# platform_designer_hps_system_hps_0_hps register map
Vendor: default_vendor.com; File version: 0.0
Registers are 32-bit, read-write, reset 0x0 unless marked. A register's access mark holds for its fields unless they carry their own. Offsets are from the block's base; [hi:lo] are bit positions.

## i2c0 — Registers in the I2C module
Base 0xFFC04000
Same registers: i2c1 0xFFC05000, i2c2 0xFFC06000, i2c3 0xFFC07000
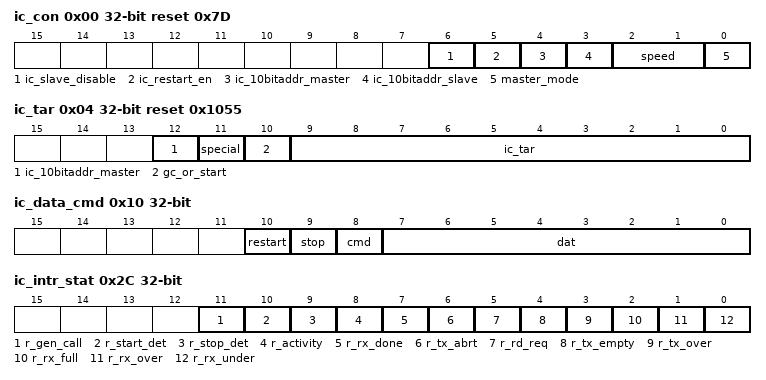
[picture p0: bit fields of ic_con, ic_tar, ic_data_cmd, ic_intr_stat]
0x00 ic_con reset 0x7D — This register can be written only when the I2C is disabled, which corresponds to the Bit [0] of the Enable Register being set to 0. Writes at other times have no effect.
  [6] ic_slave_disable — This bit controls whether I2C has its slave disabled. The slave will be disabled, after reset. NOTE: Software should ensure that if this bit is written with 0, then bit [0] of this register should also be written with a 0.
    1=disable; 0=enable
  [5] ic_restart_en — Determines whether RESTART conditions may be sent when acting as a master. Some older slaves do not support handling RESTART conditions; however, RESTART conditions are used in several I2C operations. When RESTART is disabled, the master is prohibited from performing the following functions - Changing direction within a transfer (split), - Sending a START BYTE, - High-speed mode operation, - Combined format transfers in 7-bit addressing modes, - Read operation with a 10-bit address, - Sending multiple bytes per transfer, By replacing RESTART condition followed by a STOP and a subsequent START condition, split operations are broken down into multiple I2C transfers. If the above operations are performed, it will result in setting bit [6](tx_abort) of the Raw Interrupt Status Register.
    0=disable; 1=enable
  [4] ic_10bitaddr_master — This bit controls whether the I2C starts its transfers in 7-or 10-bit addressing mode when acting as a master.
    0=mstaddr7bit; 1=mstaddr10bit
  [3] ic_10bitaddr_slave — When acting as a slave, this bit controls whether the I2C responds to 7- or 10-bit addresses. In 7-bit addressing, only the lower 7 bits of the Slave Address Register are compared. The I2C responds will only respond to 10-bit addressing transfers that match the full 10 bits of the Slave Address register.
    0=slvaddr7bit; 1=slvaddr10bit
  [2:1] speed — These bits control at which speed the I2C operates, its setting is relevant only if one is operating the I2C in master mode. Hardware protects against illegal values being programmed by software. This field should be programmed only with standard or fast speed.
    1=standard; 2=fast
  [0] master_mode — This bit controls whether the i2c master is enabled. NOTE: Software should ensure that if this bit is written with '1', then bit 6 should also be written with a '1'.
    0=disable; 1=enable
0x04 ic_tar reset 0x1055 — This register can be written to only when the ic_enable register is set to 0. This register is 13 bits wide. All bits can be dynamically updated as long as any set of the following conditions are true, (Enable Register bit 0 is set to 0) or (Enable Register bit 0 is set to 1 AND (I2C is NOT engaged in any Master [tx, rx] operation [ic_status register mst_activity bit 5 is set to 0]) AND (I2C is enabled to operate in Master mode[ic_con bit[0] is set to one]) AND (there are NO entries in the TX FIFO Register [IC_STATUS bit [2] is set to 1])
  [12] ic_10bitaddr_master — This bit controls whether the i2c starts its transfers in 7-bit or 10-bit addressing mode when acting as a master.
    0=start7; 1=start10
  [11] special — This bit indicates whether software performs a General Call or START BYTE command.
    0=gencall; 1=startbyte
  [10] gc_or_start — If bit 11 (SPECIAL) of this Register is set to 1, then this bit indicates whether a General Call or START byte command is to be performed by the I2C or General Call Address after issuing a General Call, only writes may be performed. Attempting to issue a read command results in setting bit 6 (TX_ABRT) of the Raw Interrupt_Status register. The I2C remains in General Call mode until the special bit value (bit 11) is cleared.
    0=gencall; 1=startbyte
  [9:0] ic_tar — This is the target address for any master transaction. When transmitting a General Call, these bits are ignored. To generate a START BYTE, the CPU needs to write only once into these bits. If the ic_tar and ic_sar are the same, loopback exists but the FIFOs are shared between master and slave, so full loopback is not feasible. Only one direction loopback mode is supported (simplex), not duplex. A master cannot transmit to itself; it can transmit to only a slave.
0x08 ic_sar reset 0x55 — Holds Address of Slave
  [9:0] ic_sar — The Slave Address register holds the slave address when the I2C is operating as a slave. For 7-bit addressing, only Field Bits [6:0] of the Slave Address Register are used. This register can be written only when the I2C interface is disabled, which corresponds to field bit 0 of the Enable Register being set to 0. Writes at other times have no effect. Note, the default values cannot be any of the reserved address locations: that is, 0x00 to 0x07, or 0x78 to 0x7f. The correct operation of the device is not guaranteed if you program the Slave Address Register or Target Address Register to a reserved value.
0x10 ic_data_cmd — This is the register the CPU writes to when filling the TX FIFO. Reading from this register returns bytes from RX FIFO.
  [10] restart wo — This bit controls whether a RESTART is issued before the byte is sent or received. 1 = A RESTART is issued before the data is sent/received (according to the value of CMD), regardless of whether or not the transfer direction is changing from the previous command. 0 = A RESTART is issued only if the transfer direction is changing from the previous command.
    1=restart; 0=restart_on_dir_change
  [9] stop wo — This bit controls whether a STOP is issued after the byte is sent or received. 1 = STOP is issued after this byte, regardless of whether or not the Tx FIFO is empty. If the Tx FIFO is not empty, the master immediately tries to start a new transfer by issuing a START and arbitrating for the bus. 0 = STOP is not issued after this byte, regardless of whether or not the Tx FIFO is empty. If the Tx FIFO is not empty, the master continues the current transfer by sending/receiving data bytes according to the value of the CMD bit. If the Tx FIFO is empty, the master holds the SCL line low and stalls the bus until a new command is available in the Tx FIFO.
    1=stop; 0=no_stop
  [8] cmd wo — This bit controls whether a read or a write is performed. This bit does not control the direction when the I2C acts as a slave. It controls only the direction when it acts as a master. When a command is entered in the TX FIFO, this bit distinguishes the write and read commands. In slave-receiver mode, this bit is a 'don't care' because writes to this register are not required. In slave-transmitter mode, a '0' indicates that the CPU data is to be transmitted. When programming this bit, you should remember the following: attempting to perform a read operation after a General Call command has been sent results in a tx_abrt interrupt (bit 6 of the Raw Intr Status Register), unless bit 11 special in the Target Address Register has been cleared. If a '1' is written to this bit after receiving a RD_REQ interrupt, then a tx_abrt interrupt occurs. NOTE: It is possible that while attempting a master I2C read transfer on I2C, a RD_REQ interrupt may have occurred simultaneously due to a remote I2C master addressing I2C. In this type of scenario, I2C ignores the Data Cmd write, generates a tx_abrt interrupt, and waits to service the RD_REQ interrupt.
    1=rd; 0=wr
  [7:0] dat — This Field contains the data to be transmitted or received on the I2C bus. If you are writing to these bits and want to perform a read, bits 7:0 (dat) are ignored by the I2C. However, when you read from this register, these bits return the value of data received on the I2C interface.
0x14 ic_ss_scl_hcnt reset 0x190 — This register sets the SCL clock high-period count for standard speed.
  [15:0] ic_ss_scl_hcnt — This register must be set before any I2C bus transaction can take place to ensure proper I/O timing. This field sets the SCL clock high-period count for standard speed. This register can be written only when the I2C interface is disabled which corresponds to the Enable Register being set to 0. Writes at other times have no effect. The minimum valid value is 6; hardware prevents values less than this being written, and if attempted results in 6 being set. It is readable and writeable. NOTE: This register must not be programmed to a value higher than 65525, because I2C uses a 16-bit counter to flag an I2C bus idle condition when this counter reaches a value of IC_SS_SCL_HCNT + 10.
0x18 ic_ss_scl_lcnt reset 0x1D6 — This register sets the SCL clock low-period count for standard speed
  [15:0] ic_ss_scl_lcnt — This register must be set before any I2C bus transaction can take place to ensure proper I/O timing. This field sets the SCL clock low period count for standard speed. This register can be written only when the I2C interface is disabled which corresponds to the Enable Register register being set to 0. Writes at other times have no effect. The minimum valid value is 8; hardware prevents values less than this from being written, and if attempted, results in 8 being set.
0x1C ic_fs_scl_hcnt reset 0x3C — This register sets the SCL clock high-period count for fast speed
  [15:0] ic_fs_scl_hcnt — This register must be set before any I2C bus transaction can take place to ensure proper I/O timing. This register sets the SCL clock high-period count for fast speed. It is used in high-speed mode to send the Master Code and START BYTE or General CALL. This register goes away and becomes read-only returning 0s if in Standard Speed Mode. This register can be written only when the I2C interface is disabled, which corresponds to the Enable Register being set to 0. Writes at other times have no effect. The minimum valid value is 6; hardware prevents values less than this from being written, and if attempted results in 6 being set.
0x20 ic_fs_scl_lcnt reset 0x82 — This register sets the SCL clock low period count
  [15:0] ic_fs_scl_lcnt — This register must be set before any I2C bus transaction can take place to ensure proper I/O timing. This field sets the SCL clock low period count for fast speed. It is used in high-speed mode to send the Master Code and START BYTE or General CALL. This register can be written only when the I2C interface is disabled, which corresponds to the Enable Register being set to 0. Writes at other times have no effect.The minimum valid value is 8; hardware prevents values less than this being written, and if attempted results in 8 being set.
0x2C ic_intr_stat ro — Each bit in this register has a corresponding mask bit in the Interrupt Mask Register. These bits are cleared by reading the matching Interrupt Clear Register. The unmasked raw versions of these bits are available in the Raw Interrupt Status Register.
  [11] r_gen_call — Set only when a General Call address is received and it is acknowledged. It stays set until it is cleared either by disabling I2C or when the CPU reads bit 0 of the ic_clr_gen_call register. I2C stores the received data in the Rx buffer.
  [10] r_start_det — Indicates whether a START or RESTART condition has occurred on the I2C interface regardless of whether I2C is operating in slave or master mode.
  [9] r_stop_det — Indicates whether a STOP condition has occurred on the I2C interface regardless of whether I2C is operating in slave or master mode.
  [8] r_activity — This bit captures I2C activity and stays set until it is cleared. There are four ways to clear it: - Disabling the I2C - Reading the ic_clr_activity register - Reading the ic_clr_intr register - I2C reset Once this bit is set, it stays set unless one of the four methods is used to clear it. Even if the I2C module is idle, this bit remains set until cleared, indicating that there was activity on the bus.
  [7] r_rx_done — When the I2C is acting as a slave-transmitter, this bit is set to 1, if the master does not acknowledge a transmitted byte. This occurs on the last byte of the transmission, indicating that the transmission is done.
  [6] r_tx_abrt — This bit indicates if I2C, as an I2C transmitter, is unable to complete the intended actions on the contents of the transmit FIFO. This situation can occur both as an I2C master or an I2C slave, and is referred to as a 'transmit abort'.When this bit is set to 1, the ic_tx_abrt_source register indicates the reason why the transmit abort takes places. NOTE: The I2C flushes/resets/empties the TX FIFO whenever this bit is set. The TX FIFO remains in this flushed state until the register ic_clr_tx_abrt is read. Once this read is performed, the TX FIFO is then ready to accept more data bytes from the APB interface.
  [5] r_rd_req — This bit is set to 1 when i2c is acting as a slave and another I2C master is attempting to read data from I2C. The I2C holds the I2C bus in a wait state (SCL=0) until this interrupt is serviced, which means that the slave has been addressed by a remote master that is asking for data to be transferred. The processor must respond to this interrupt and then write the requested data to the IC_DATA_CMD register. This bit is set to 0 just after the processor reads the ic_clr_rd_req register.
  [4] r_tx_empty — This bit is set to 1 when the transmit buffer is at or below the threshold value set in the ic_tx_tl register. It is automatically cleared by hardware when the buffer level goes above the threshold. When the ic_enable bit 0 is 0, the TX FIFO is flushed and held in reset. There the TX FIFO looks like it has no data within it, so this bit is set to 1, provided there is activity in the master or slave state machines. When there is no longer activity, this bit is set to 0.
  [3] r_tx_over — Set during transmit if the transmit buffer is filled to 64 and the processor attempts to issue another I2C command by writing to the Data and Command Register. When the module is disabled, this bit keeps its level until the master or slave state machines goes into idle, then interrupt is cleared.
  [2] r_rx_full — Set when the receive buffer reaches or goes above the Receive FIFO Threshold Value(rx_tl). It is automatically cleared by hardware when buffer level goes below the threshold. If the module is disabled, Bit [0] of the Enable Register set to 0, the RX FIFO is flushed and held in reset; therefore the RX FIFO is not full. So this bit is cleared once the Enable Register Bit 0 is programmed with a 0, regardless of the activity that continues.
  [1] r_rx_over — Set if the receive buffer is completely filled to 64 and an additional byte is received from an external I2C device. The I2C acknowledges this, but any data bytes received after the FIFO is full are lost. If the module is disabled, Enable Register bit[0] is set to 0 this bit keeps its level until the master or slave state machines go into idle, then this interrupt is cleared.
  [0] r_rx_under — Set if the processor attempts to read the receive buffer when it is empty by reading from the Tx Rx Data and Command Register. If the module is disabled, Enable Register is set to 0, this bit keeps its level until the master or slave state machines go into idle, then this interrupt is cleared.
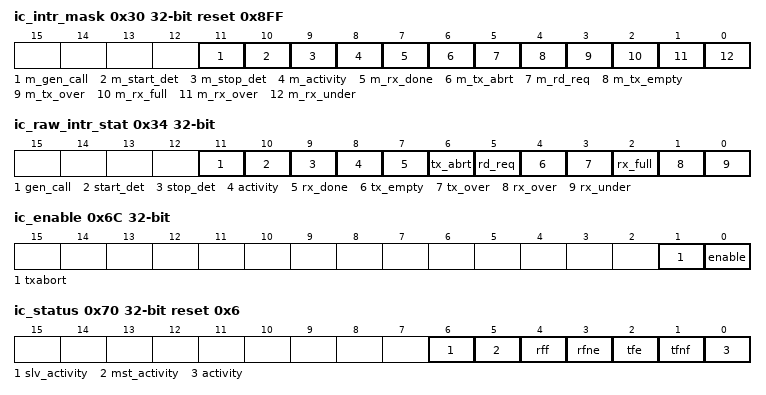
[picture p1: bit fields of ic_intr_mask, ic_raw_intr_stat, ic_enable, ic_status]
0x30 ic_intr_mask reset 0x8FF — These bits mask their corresponding interrupt status bits.
  [11] m_gen_call — Set only when a General Call address is received and it is acknowledged. It stays set until it is cleared either by disabling I2C or when the CPU reads bit 0 of the ic_clr_gen_call register. I2C stores the received data in the Rx buffer.
  [10] m_start_det — Indicates whether a START or RESTART condition has occurred on the I2C interface regardless of whether I2C is operating in slave or master mode.
  [9] m_stop_det — Indicates whether a STOP condition has occurred on the I2C interface regardless of whether i2c is operating in slave or master mode.
  [8] m_activity — This bit captures i2c activity and stays set until it is cleared. There are four ways to clear it: - Disabling the i2c - Reading the ic_clr_activity register - Reading the ic_clr_intr register - System reset Once this bit is set, it stays set unless one of the four methods is used to clear it. Even if the I2C module is idle, this bit remains set until cleared, indicating that there was activity on the bus.
  [7] m_rx_done — When the I2C is acting as a slave-transmitter, this bit is set to 1, if the master does not acknowledge a transmitted byte. This occurs on the last byte of the transmission, indicating that the transmission is done.
  [6] m_tx_abrt — This bit indicates if I2C, as an I2C transmitter, is unable to complete the intended actions on the contents of the transmit FIFO. This situation can occur both as an I2C master or an I2C slave, and is referred to as a 'transmit abort'. When this bit is set to 1, the ic_tx_abrt_source register indicates the reason why the transmit abort takes places. NOTE: The I2C flushes/resets/empties the TX FIFO whenever this bit is set. The TX FIFO remains in this flushed state until the register ic_clr_tx_abrt is read. Once this read is performed, the TX FIFO is then ready to accept more data bytes from the APB interface.
  [5] m_rd_req — This bit is set to 1 when I2C is acting as a slave and another I2C master is attempting to read data from I2C. The I2C holds the I2C bus in a wait state (SCL=0) until this interrupt is serviced, which means that the slave has been addressed by a remote master that is asking for data to be transferred. The processor must respond to this interrupt and then write the requested data to the ic_data_cmd register. This bit is set to 0 just after the processor reads the ic_clr_rd_req register.
  [4] m_tx_empty — This bit is set to 1 when the transmit buffer is at or below the threshold value set in the ic_tx_tl register. It is automatically cleared by hardware when the buffer level goes above the threshold. When the ic_enable bit 0 is 0, the TX FIFO is flushed and held in reset. There the TX FIFO looks like it has no data within it, so this bit is set to 1, provided there is activity in the master or slave state machines. When there is no longer activity, then this bit is set to 0.
  [3] m_tx_over — Set during transmit if the transmit buffer is filled to 64 and the processor attempts to issue another I2C command by writing to the ic_data_cmd register. When the module is disabled, this bit keeps its level until the master or slave state machines go into idle, then this interrupt is cleared.
  [2] m_rx_full — Set when the receive buffer reaches or goes above the RX_TL threshold in the ic_rx_tl register. It is automatically cleared by hardware when buffer level goes below the threshold. If the module is disabled ic_enable[0]=0, the RX FIFO is flushed and held in reset; therefore the RX FIFO is not full. So this bit is cleared once the ic_enable bit 0 is programmed with a 0, regardless of the activity that continues.
  [1] m_rx_over — Set if the receive buffer is completely filled to 64 and an additional byte is received from an external I2C device. The I2C acknowledges this, but any data bytes received after the FIFO is full are lost. If the module is disabled ic_enable[0]=0, this bit keeps its level until the master or slave state machines go into idle, then this interrupt is cleared.
  [0] m_rx_under — Set if the processor attempts to read the receive buffer when it is empty by reading from the ic_data_cmd register. If the module is disabled ic_enable[0]=0, this bit keeps its level until the master or slave state machines go into idle, and then this interrupt is cleared.
0x34 ic_raw_intr_stat ro — Unlike the ic_intr_stat register, these bits are not masked so they always show the true status of the I2C.
  [11] gen_call — Set only when a General Call address is received and it is acknowledged. It stays set until it is cleared either by disabling I2C or when the CPU reads bit 0 of the ic_clr_gen_call register. I2C stores the received data in the Rx buffer.
  [10] start_det — Indicates whether a START or RESTART condition has occurred on the I2C interface regardless of whether I2C is operating in slave or master mode.
  [9] stop_det — Indicates whether a STOP condition has occurred on the I2C interface regardless of whether I2C is operating in slave or master mode.
  [8] activity — This bit captures i2c activity and stays set until it is cleared. There are four ways to clear it: - Disabling the I2C - Reading the ic_clr_activity register - Reading the ic_clr_intr register - System reset Once this bit is set, it stays set unless one of the four methods is used to clear it. Even if the i2c module is idle, this bit remains set until cleared, indicating that there was activity on the bus.
  [7] rx_done — When the I2C is acting as a slave-transmitter, this bit is set to 1 if the master does not acknowledge a transmitted byte. This occurs on the last byte of the transmission, indicating that the transmission is done.
  [6] tx_abrt — This bit indicates if I2C, as an I2C transmitter, is unable to complete the intended actions on the contents of the transmit FIFO. This situation can occur both as an I2C master or an I2C slave, and is referred to as a 'transmit abort'. When this bit is set to 1, the IC_TX_ABRT_SOURCE register indicates the reason why the transmit abort takes places. NOTE: The I2C flushes/resets/empties the TX FIFO whenever this bit is set. The TX FIFO remains in this flushed state until the register ic_clr_tx_abrt is read. Once this read is performed, the TX FIFO is then ready to accept more data bytes from the APB interface.
  [5] rd_req — This bit is set to 1 when I2C is acting as a slave and another I2C master is attempting to read data from I2C. The i2c holds the I2C bus in a wait state (SCL=0) until this interrupt is serviced, which means that the slave has been addressed by a remote master that is asking for data to be transferred. The processor must respond to this interrupt and then write the requested data to the ic_data_cmd register. This bit is set to 0 just after the processor reads the ic_clr_rd_req register.
  [4] tx_empty — This bit is set to 1 when the transmit buffer is at or below the threshold value set in the ic_tx_tl register. It is automatically cleared by hardware when the buffer level goes above the threshold. When the IC_ENABLE bit 0 is 0, the TX FIFO is flushed and held in reset. There the TX FIFO looks like it has no data within it, so this bit is set to 1, provided there is activity in the master or slave state machines. When there is no longer activity, then this bit is set to 0.
  [3] tx_over — Set during transmit if the transmit buffer is filled to 64 and the processor attempts to issue another I2C command by writing to the ic_data_cmd register. When the module is disabled, this bit keeps its level until the master or slave state machines go into idle, then this interrupt is cleared.
  [2] rx_full — Set when the receive buffer reaches or goes above the RX_TL threshold in the ic_rx_tl register. It is automatically cleared by hardware when buffer level goes below the threshold. If the module is disabled ic_enable[0]=0, the RX FIFO is flushed and held in reset; therefore the RX FIFO is not full. So this bit is cleared once the ic_enable bit 0 is programmed with a 0, regardless of the activity that continues.
  [1] rx_over — Set if the receive buffer is completely filled to 64 and an additional byte is received from an external I2C device. The I2C acknowledges this, but any data bytes received after the FIFO is full are lost. If the module is disabled ic_enable[0]=0), this bit keeps its level until the master or slave state machines go into then, this interrupt is cleared.
  [0] rx_under — Set if the processor attempts to read the receive buffer when it is empty by reading from the ic_data_cmd register. If the module is disabled ic_enable[0]=0, this bit keeps its level until the master or slave state machines go into idle, then this interrupt is cleared.
0x38 ic_rx_tl — I2C Receive FIFO Threshold Register.
  [7:0] rx_tl — Controls the level of entries (or above) that triggers the RX_FULL interrupt (bit 2 in IC_RAW_INTR_STAT register). The valid range is 0-255, with the additional restriction that hardware does not allow this value to be set to a value larger than the depth of the buffer. If an attempt is made to do that, the actual value set will be the maximum depth of the buffer. A value of 0 sets the threshold for 1 entry, and a value of 255 sets the threshold for 256 entries.
0x3C ic_tx_tl — Sets FIFO depth for Interrupt.
  [7:0] tx_tl — Controls the level of entries (or below) that trigger the TX_EMPTY interrupt (bit 4 in ic_raw_intr_stat register). The valid range is 0-255, with the additional restriction that it may not be set to value larger than the depth of the buffer. If an attempt is made to do that, the actual value set will be the maximum depth of the buffer. A value of 0 sets the threshold for 0 entries, and a value of 255 sets the threshold for 255 entries.
0x40 ic_clr_intr ro — Controls Interrupts
  [0] clr_intr — Read this register to clear the combined interrupt, all individual interrupts, and the IC_TX_ABRT_SOURCE register. This bit does not clear hardware clearable interrupts but software clearable interrupts. Refer to Bit 9 of the ic_tx_abrt_source register for an exception to clearing ic_tx_abrt_source.
0x44 ic_clr_rx_under ro — Rx Under Interrupt Bits.
  [0] clr_rx_under — Read this register to clear the RX_UNDER interrupt bit 0 of the ic_raw_intr_stat register.
0x48 ic_clr_rx_over ro — Clears Rx over Interrupt Bit
  [0] clr_rx_over — Read this register to clear the RX_OVER interrupt bit 1 of the ic_raw_intr_stat register.
0x4C ic_clr_tx_over ro — Clears Over Interrupts
  [0] clr_tx_over — Read this register to clear the TX_OVER interrupt (bit 3) of the ic_raw_intr_stat register.
0x50 ic_clr_rd_req ro — Clear RD_REQ Interrupt Register
  [0] clr_rd_req — Read this register to clear the RD_REQ interrupt (bit 5) of the ic_raw_intr_stat register.
0x54 ic_clr_tx_abrt ro — Clear TX_ABRT Interrupt
  [0] clr_tx_abort — Read this register to clear the TX_ABRT interrupt (bit 6) of the ic_raw_intr_stat register, and the ic_tx_abrt_source register. This also releases the TX FIFO from the flushed/reset state, allowing more writes to the TX FIFO. Refer to Bit 9 of the ic_tx_abrt_source register for an exception to clearing ic_tx_abrt_source.
0x58 ic_clr_rx_done ro — Clear RX_DONE Interrupt Register
  [0] clr_rx_done — Read this register to clear the RX_DONE interrupt (bit 7) of the ic_raw_intr_stat register.
0x5C ic_clr_activity ro — Clears ACTIVITY Interrupt
  [0] clr_activity — Reading this register clears the ACTIVITY interrupt if the I2C is not active anymore. If the I2C module is still active on the bus, the ACTIVITY interrupt bit continues to be set. It is automatically cleared by hardware if the module is disabled and if there is no further activity on the bus. The value read from this register to get status of the ACTIVITY interrupt (bit 8) of the ic_raw_intr_stat register.
0x60 ic_clr_stop_det ro — Clear Interrupts.
  [0] clr_stop_det — Read this register to clear the clr_stop_det interrupt (bit 9) of the ic_raw_intr_stat register.
0x64 ic_clr_start_det ro — Clears START_DET Interrupt
  [0] clr_start_det — Read this register to clear the start_det interrupt (bit 10) of the ic_raw_intr_stat register.
0x68 ic_clr_gen_call ro — Clear GEN_CALL Interrupt Register
  [0] clr_gen_call — Read this register to clear the GEN_CALL interrupt (bit 11) of ic_raw_intr_stat register.
0x6C ic_enable — Enable and disable i2c operation
  [1] txabort — Write 1 does a TX abort. Self cleared on abort completion
  [0] enable — Controls whether the I2C is enabled. Software can disable I2C while it is active. However, it is important that care be taken to ensure that I2C is disabled properly. When the I2C is disabled, the following occurs: The TX FIFO and RX FIFO get flushed. Status bits in the IC_INTR_STAT register are still active until I2C goes into IDLE state. If the module is transmitting, it stops as well as deletes the contents of the transmit buffer after the current transfer is complete. If the module is receiving, the I2C stops the current transfer at the end of the current byte and does not acknowledge the transfer. The l4_sp_clk synchronizes pclk and ic_clk. The register ic_enable_status is added to allow software to determine when the hardware has completely shutdown in response to the IC_ENABLE register being set from 1 to 0. Only one register is required to be monitored. Procedure for Disabling I2C 1. Define a timer interval (ti2c_poll) equal to the 10 times the signaling period for the highest I2C transfer speed used in the system and supported by I2C. For example, if the highest I2C transfer mode is 400 kb/s, then this ti2c_poll is 25us. 2. Define a maximum time-out parameter, MAX_T_POLL_COUNT, such that if any repeated polling operation exceeds this maximum value, an error is reported. 3. Execute a blocking thread/process/function that prevents any further I2C master transactions to be started by software, but allows any pending transfers to be completed. 4. The variable POLL_COUNT is initialized to zero. 5. Set IC_ENABLE to 0. 6. Read the IC_ENABLE_STATUS register and test the IC_EN bit (bit 0). Increment POLL_COUNT by one. If POLL_COUNT >= MAX_T_POLL_COUNT, exit with the relevant error code. 7. If IC_ENABLE_STATUS[0] is 1, then sleep for ti2c_poll and proceed to the previous step. Otherwise, exit with a relevant success code.
    0=disable; 1=enable
0x70 ic_status ro reset 0x6 — This is a read-only register used to indicate the current transfer status and FIFO status. The status register may be read at any time. None of the bits in this register request an interrupt.When the I2C is disabled by writing 0 in bit 0 of the ic_enable register: - Bits 1 and 2 are set to 1 - Bits 3 and 4 are set to 0 When the master or slave state machines goes to idle - Bits 5 and 6 are set to 0
  [6] slv_activity — Slave FSM Activity Status. When the Slave Finite State Machine (FSM) is not in the IDLE state, this bit is set.
    0=idle; 1=notidle
  [5] mst_activity — When the Master Finite State Machine (FSM) is not in the IDLE state, this bit is set. Note:IC_STATUS[0]-that is, ACTIVITY bit-is the OR of SLV_ACTIVITY and MST_ACTIVITY bits.
    0=idle; 1=notidle
  [4] rff — Receive FIFO Completely Full.
    0=notfull; 1=full
  [3] rfne — Receive FIFO Not Empty.
    0=empty; 1=notempty
  [2] tfe — Transmit FIFO Empty.
    0=notempty; 1=empty
  [1] tfnf — Transmit Fifo Full
    0=full; 1=notfull
  [0] activity — I2C Activity.
0x74 ic_txflr ro — This register contains the number of valid data entries in the transmit FIFO buffer. It is cleared whenever: - The I2C is disabled - There is a transmit abort that is, TX_ABRT bit is set in the ic_raw_intr_stat register. The slave bulk transmit mode is aborted The register increments whenever data is placed into the transmit FIFO and decrements when data is taken from the transmit FIFO.
  [6:0] txflr — Transmit FIFO Level.Contains the number of valid data entries in the transmit FIFO.
0x78 ic_rxflr ro — This register contains the number of valid data entries in the receive FIFO buffer. It is cleared whenever: - The I2C is disabled - Whenever there is a transmit abort caused by any of the events tracked in ic_tx_abrt_source The register increments whenever data is placed into the receive FIFO and decrements when data is taken from the receive FIFO.
  [6:0] rxflr — Receive FIFO Level. Contains the number of valid data entries in the receive FIFO.
0x7C ic_sda_hold reset 0x1 — This register controls the amount of time delay (in terms of number of l4_sp_clk clock periods) introduced in the falling edge of SCL, relative to SDA changing, when I2C services a read request in a slave-transmitter operation. The relevant I2C requirement is thd:DAT as detailed in the I2C Bus Specification.
  [15:0] ic_sda_hold — Program to a minimum 0f 300ns.
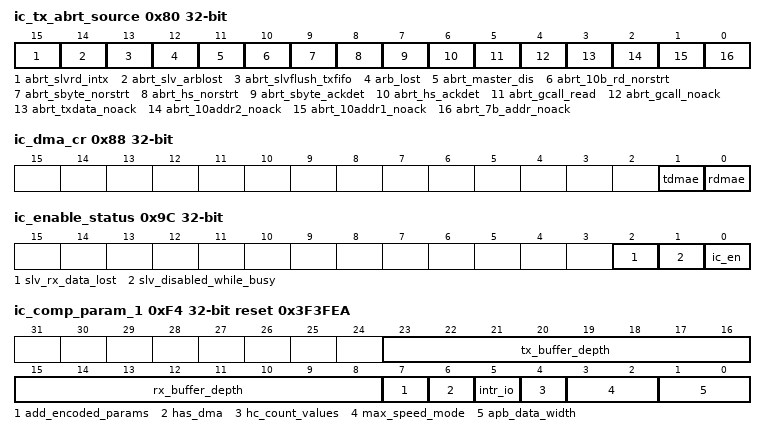
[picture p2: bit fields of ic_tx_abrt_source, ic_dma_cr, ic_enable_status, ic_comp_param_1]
0x80 ic_tx_abrt_source — This register has 16 bits that indicate the source of the TX_ABRT bit. Except for Bit 9, this register is cleared whenever the ic_clr_tx_abrt register or the ic_clr_intr register is read. To clear Bit 9, the source of the abrt_sbyte_norstrt must be fixed first; RESTART must be enabled (ic_con[5]=1), the special bit must be cleared (ic_tar[11]), or the gc_or_start bit must be cleared (ic_tar[10]). Once the source of the abrt_sbyte_norstrt is fixed, then this bit can be cleared in the same manner as other bits in this register. If the source of the abrt_sbyte_norstrt is not fixed before attempting to clear this bit, Bit 9 clears for one cycle and is then re-asserted.
  [15] abrt_slvrd_intx — When the processor side responds to a slave mode request for data to be transmitted to a remote master and user writes a 1 in CMD (bit 8) of IC_DATA_CMD register. Role of I2C: Slave-Transmitter
  [14] abrt_slv_arblost — Slave lost the bus while transmitting data to a remote master. IC_TX_ABRT_SOURCE[12] is set at the same time. Note: Even though the slave never 'owns' the bus, something could go wrong on the bus. This is a fail safe check. For instance, during a data transmission at the low-to-high transition of SCL, if what is on the data bus is not what is supposed to be transmitted, then i2c no longer own the bus. Role of I2C: Slave-Transmitter
  [13] abrt_slvflush_txfifo — Slave has received a read command and some data exists in the TX FIFO so the slave issues a TX_ABRT interrupt to flush old data in TX FIFO. Role of I2C: Slave-Transmitter
  [12] arb_lost — Master has lost arbitration, or if IC_TX_ABRT_SOURCE[14] is also set, then the slave transmitter has lost arbitration. Note: I2C can be both master and slave at the same time. Role of i2c: Master-Transmitter or Slave-Transmitter
  [11] abrt_master_dis — User tries to initiate a Master operation with the Master mode disabled. Role of I2C: Master-Transmitter or Master-Receiver
  [10] abrt_10b_rd_norstrt — The restart is disabled (ic_restart_en bit (ic_con[5]) =0) and the master sends a read command in 10-bit addressing mode. Role of I2C: Master-Receiver
  [9] abrt_sbyte_norstrt — To clear Bit 9, the source of then abrt_sbyte_norstrt must be fixed first; restart must be enabled (ic_con[5]=1), the SPECIAL bit must be cleared (ic_tar[11]), or the GC_OR_START bit must be cleared (ic_tar[10]). Once the source of the abrt_sbyte_norstrt is fixed, then this bit can be cleared in the same manner as other bits in this register. If the source of the abrt_sbyte_norstrt is not fixed before attempting to clear this bit, bit 9 clears for one cycle and then gets reasserted. 1: The restart is disabled (IC_RESTART_EN bit (ic_con[5]) =0) and the user is trying to send a START Byte. Role of I2C: Master
  [8] abrt_hs_norstrt — The restart is disabled (IC_RESTART_EN bit (IC_CON[5]) =0) and the user is trying to use the master to transfer data in High Speed mode. Role of i2c: Master-Transmitter or Master-Receiver
  [7] abrt_sbyte_ackdet — Master has sent a START Byte and the START Byte was acknowledged (wrong behavior). Role of i2c: Master
  [6] abrt_hs_ackdet — Master is in High Speed mode and the High Speed Master code was acknowledged (wrong behavior). Role of i2c: Master
  [5] abrt_gcall_read — i2c in master mode sent a General Call but the user programmed the byte following the General Call to be a read from the bus (IC_DATA_CMD[9] is set to 1). Role of i2c: Master-Transmitter
  [4] abrt_gcall_noack — i2c in master mode sent a General Call and no slave on the bus acknowledged the General Call. Role of i2c: Master-Transmitter
  [3] abrt_txdata_noack — This is a master-mode only bit. Master has received an acknowledgement for the address, but when it sent data byte(s) following the address, it did not receive an acknowledge from the remote slave(s). Role of i2c: Master-Transmitter
  [2] abrt_10addr2_noack — Master is in 10-bit address mode and the second address byte of the 10-bit address was not acknowledged by any slave. Role of i2c: Master-Transmitter or Master-Receiver
  [1] abrt_10addr1_noack — Master is in 10-bit address mode and the first 10-bit address byte was not acknowledged by any slave. Role of i2c: Master-Transmitter or Master-Receiver
  [0] abrt_7b_addr_noack — Master is in 7-bit addressing mode and the address sent was not acknowledged by any slave. Role of i2c: Master-Transmitter or Master-Receiver
0x84 ic_slv_data_nack_only — The register is used to generate a NACK for the data part of a transfer when i2c is acting as a slave-receiver.
  [0] nack — This Bit control Nack generation
    1=afterdbyte; 0=norm
0x88 ic_dma_cr — The register is used to enable the DMA Controller interface operation. There is a separate bit for transmit and receive. This can be programmed regardless of the state of IC_ENABLE.
  [1] tdmae — This bit enables/disables the transmit FIFO DMA channel.
    0=disable; 1=enable
  [0] rdmae — This bit enables/disables the receive FIFO DMA channel.
    0=disable; 1=enable
0x8C ic_dma_tdlr — This register supports DMA Transmit Operation.
  [5:0] dmatdl — This bit field controls the level at which a DMA request is made by the transmit logic. It is equal to the watermark level; that is, the i2c_dma_tx_req signal is generated when the number of valid data entries in the transmit FIFO is equal to or below this field value, and TDMAE = 1.
0x90 ic_dma_rdlr — DMA Control Signals Interface.
  [5:0] dmardl — This bit field controls the level at which a DMA request is made by the receive logic. The watermark level \= DMARDL+1; that is, dma_rx_req is generated when the number of valid data entries in the receive FIFO is equal to or more than this field value + 1, and RDMAE =1. For instance, when DMARDL is 0, then dma_rx_req is asserted when or more data entries are present in the receive FIFO.
0x94 ic_sda_setup reset 0x64 — This register controls the amount of time delay (in terms of number of l4_sp_clk clock periods) introduced in the rising edge of SCL relative to SDA changing by holding SCL low when I2C services a read request while operating as a slave-transmitter. The relevant I2C requirement is tSU:DAT (note 4) as detailed in the I2C Bus Specification. This register must be programmed with a value equal to or greater than 2. Note: The length of setup time is calculated using [(IC_SDA_SETUP - 1) * (l4_sp_clk)], so if the user requires 10 l4_sp_clk periods of setup time, they should program a value of 11. The IC_SDA_SETUP register is only used by the I2C when operating as a slave transmitter.
  [7:0] sda_setup — It is recommended that if the required delay is 1000ns, then for an l4_sp_clk frequency of 10 MHz, ic_sda_setup should be programmed to a value of 11.
0x98 ic_ack_general_call reset 0x1 — The register controls whether i2c responds with a ACK or NACK when it receives an I2C General Call address.
  [0] ack_gen_call — When an ACK is asserted, (by asserting i2c_out_data) when it receives a General call. Otherwise, i2c responds with a NACK (by negating i2c_out_data).
    0=nack; 1=ack
0x9C ic_enable_status ro — This register is used to report the i2c hardware status when the IC_ENABLE register is set from 1 to 0; that is, when i2c is disabled. If IC_ENABLE has been set to 1, bits 2:1 are forced to 0, and bit 0 is forced to 1. If IC_ENABLE has been set to 0, bits 2:1 are only valid as soon as bit 0 is read as '0'. Note: When ic_enable has been written with '0' a delay occurs for bit 0 to be read as '0' because disabling the i2c depends on I2C bus activities.
  [2] slv_rx_data_lost — This bit indicates if a Slave-Receiver operation has been aborted with at least one data byte received from an I2C transfer due to the setting of IC ENABLE from 1 to 0. When read as 1, i2c is deemed to have been actively engaged in an aborted I2C transfer (with matching address) and the data phase of the I2C transfer has been entered, even though a data byte has been responded with a NACK. NOTE: If the remote I2C master terminates the transfer with a STOP condition before the i2c has a chance to NACK a transfer, and ic_enable has been set to 0, then this bit is also set to 1. When read as 0, i2c is deemed to have been disabled without being actively involved in the data phase of a Slave-Receiver transfer. NOTE: The CPU can safely read this bit when IC_EN (bit 0) is read as 0.
  [1] slv_disabled_while_busy — This bit indicates if a potential or active Slave operation has been aborted due to the setting of the ic_enable register from 1 to 0. This bit is set when the CPU writes a 0 to the ic_enable register while: (a) I2C is receiving the address byte of the Slave-Transmitter operation from a remote master; OR, (b) address and data bytes of the Slave-Receiver operation from a remote master. When read as 1, I2C is deemed to have forced a NACK during any part of an I2C transfer, irrespective of whether the I2C address matches the slave address set in i2c (IC_SAR register) OR if the transfer is completed before IC_ENABLE is set to 0 but has not taken effect. NOTE: If the remote I2C master terminates the transfer with a STOP condition before the i2c has a chance to NACK a transfer, and IC_ENABLE has been set to 0, then this bit will also be set to 1. When read as 0, i2c is deemed to have been disabled when there is master activity, or when the I2C bus is idle. NOTE: The CPU can safely read this bit when IC_EN (bit 0) is read as 0.
  [0] ic_en — This bit always reflects the value driven on the output port ic_en. Not used in current application. When read as 1, i2c is deemed to be in an enabled state. When read as 0, i2c is deemed completely inactive. NOTE: The CPU can safely read this bit anytime. When this bit is read as 0, the CPU can safely read slv_rx_data_lost (bit 2) and slv_disabled_while_busy (bit 1).
0xA0 ic_fs_spklen reset 0x2 — This register is used to store the duration, measured in ic_clk cycles, of the longest spike that is filtered out by the spike suppression logic when the component is operating in SS or FS modes.
  [7:0] spklen — This register must be set before any I2C bus transaction can take place to ensure stable operation. This register sets the duration, measured in ic_clk cycles, of the longest spike in the SCL or SDA lines that are filtered out by the spike suppression logic. This register can be written only when the I2C interface is disabled, which corresponds to the IC_ENABLE register being set to 0. Writes at other times have no effect. The minimum valid value is 1; hardware prevents values less than this being written, and if attempted results in 2 being set.
0xF4 ic_comp_param_1 ro reset 0x3F3FEA — This is a constant read-only register that contains encoded information about the component's parameter settings.
  [23:16] tx_buffer_depth — Sets Tx FIFO Depth.
    64=fifo64bytes
  [15:8] rx_buffer_depth — Sets Rx FIFO Depth.
    64=fifo64bytes
  [7] add_encoded_params — By adding in the encoded parameters, this gives firmware an easy and quick way of identifying the DesignWare component within an I/O memory map. Some critical design-time options determine how a driver should interact with the peripheral. There is a minimal area overhead by including these parameters. Allows a single driver to be developed for each component which will be self-configurable.
    1=addencparams
  [6] has_dma — This configures the inclusion of DMA handshaking interface signals.
    1=present
  [5] intr_io — All interrupt sources are combined in to a single output.
    1=combined
  [4] hc_count_values — This makes the *CNT registers readable and writable.
    0=readwrite
  [3:2] max_speed_mode — The value of this field determines the maximum i2c bus interface speed.
    2=fast
  [1:0] apb_data_width — Sets the APB Data Width.
    2=width32bits
0xF8 ic_comp_version ro reset 0x3132302A — Describes the version of the I2C
  [31:0] ic_comp_version — Specifies I2C release number (encoded as 4 ASCII characters)
    0x3132302A=ver_1_20a
0xFC ic_comp_type ro reset 0x44570140 — Describes a unique ASCII value
  [31:0] ic_comp_type — Designware Component Type number = 0x44_57_01_40. This assigned unique hex value is constant and is derived from the two ASCII letters 'DW' followed by a 16-bit unsigned number.
